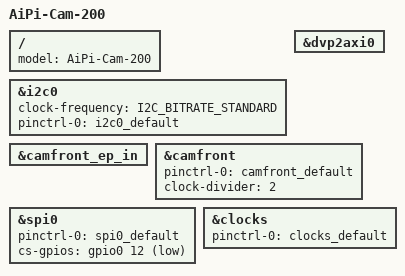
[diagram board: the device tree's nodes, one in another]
/*
 * Copyright (c) 2026 Panoramix Labs
 *
 * SPDX-License-Identifier: Apache-2.0
 */

#include "aipi_cam_d200-pinctrl.dtsi"

/ {
	model = "AiPi-Cam-200";
};

dvp_24pin_i2c: &i2c0 {
	status = "okay";

	clock-frequency = <I2C_BITRATE_STANDARD>;

	pinctrl-0 = <&i2c0_default>;
	pinctrl-names = "default";
};

dvp_24pin_interface: &dvp2axi0 {};

dvp_24pin_ep_in: &camfront_ep_in {};

&camfront {
	status = "okay";

	pinctrl-0 = <&camfront_default>;
	pinctrl-names = "default";
	clock-divider = <2>;
};

&spi0 {
	status = "okay";

	pinctrl-0 = <&spi0_default>;
	pinctrl-names = "default";

	/* shared between SD card and display, use only one */
	cs-gpios = <&gpio0 12 GPIO_ACTIVE_LOW>;
};

&clocks {
	/* for MCLK */
	pinctrl-0 = <&clocks_default>;
	pinctrl-names = "default";
};
